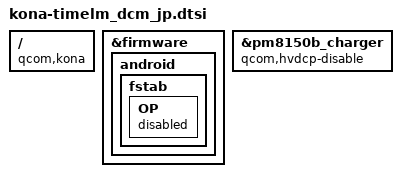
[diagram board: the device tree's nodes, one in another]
// SPDX-License-Identifier: GPL-2.0-only
/*
 * LG V60 ThinQ 5G (timelm) dcm_jp, 4.19 CONFIG_MACH_KONA_TIMELM_DCM_JP.
 * Shared by the kona-timelm_dcm_jp_rev-*.dts leaves, as LG
 * kona-timelm_dcm_jp/kona-timelm_dcm_jp.dtsi is shared by its rev overlays.
 */

/* Sony CXD2252 NFC (stock cxd22xx-i2c@28 on qupv3_se1_i2c) */
#include "kona-timelm-nfc.dtsi"

/ {
	compatible = "qcom,kona", "lg,timelm";
};

/* JP partition tables have no OP; a crossflashed phone has one, leave it unused */
&firmware {
	android {
		fstab {
			OP {
				status = "disabled";
			};
		};
	};
};

/*
 * Stock dcm_jp has lge,hvdcp-disable-user (kona-timelm_dcm_jp-pm.dtsi,
 * v60-live.dts); the 5.15 smb5 only reads qcom,hvdcp-disable.
 */
&pm8150b_charger {
	qcom,hvdcp-disable;
};
